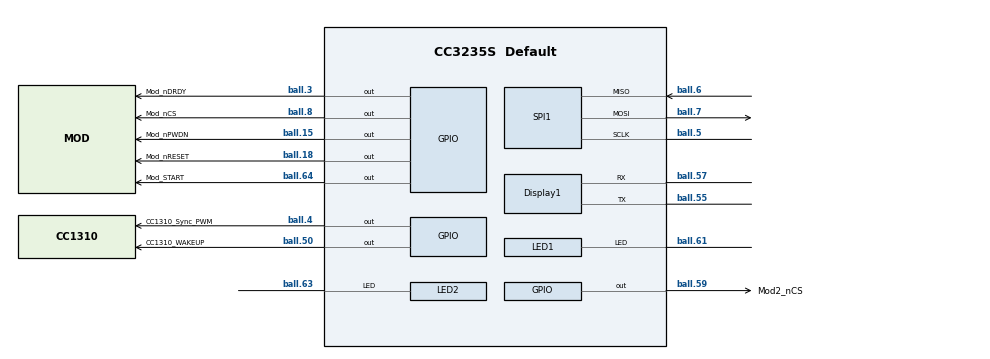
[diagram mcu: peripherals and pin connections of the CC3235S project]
/**
 * @cliArgs --device "CC3235S" --package "Default" --part "Default" --rtos "tirtos" --product "simplelink_cc32xx_sdk@5.30.00.08"
 * @versions {"tool":"1.10.0+2163"}
 */

/**
 * Import the modules used in this configuration.
 */
const DriverLib      = scripting.addModule("/ti/devices/DriverLib");
const Display        = scripting.addModule("/ti/display/Display");
const Display1       = Display.addInstance();
const Board          = scripting.addModule("/ti/drivers/Board");
const Crypto         = scripting.addModule("/ti/drivers/Crypto");
const Crypto1        = Crypto.addInstance();
const DMA            = scripting.addModule("/ti/drivers/DMA");
const GPIO           = scripting.addModule("/ti/drivers/GPIO");
const GPIO1          = GPIO.addInstance();
const GPIO2          = GPIO.addInstance();
const GPIO3          = GPIO.addInstance();
const GPIO4          = GPIO.addInstance();
const GPIO5          = GPIO.addInstance();
const GPIO6          = GPIO.addInstance();
const GPIO7          = GPIO.addInstance();
const GPIO8          = GPIO.addInstance();
const I2C            = scripting.addModule("/ti/drivers/I2C", {}, false);
const I2C1           = I2C.addInstance();
const Power          = scripting.addModule("/ti/drivers/Power");
const SPI            = scripting.addModule("/ti/drivers/SPI");
const SPI1           = SPI.addInstance();
const Timer          = scripting.addModule("/ti/drivers/Timer", {}, false);
const Timer1         = Timer.addInstance();
const Timer2         = Timer.addInstance();
const Watchdog       = scripting.addModule("/ti/drivers/Watchdog");
const Watchdog1      = Watchdog.addInstance();
const LED            = scripting.addModule("/ti/drivers/apps/LED", {}, false);
const LED1           = LED.addInstance();
const LED2           = LED.addInstance();
const SimpleLinkWifi = scripting.addModule("/ti/drivers/net/wifi/SimpleLinkWifi");
const net_utils      = scripting.addModule("/ti/drivers/net/wifi/net_utils", {}, false);
const net_utils1     = net_utils.addInstance();
const SNTP           = scripting.addModule("/ti/net/SNTP");
const SlNet          = scripting.addModule("/ti/net/SlNet");
const SlNet1         = SlNet.addInstance();
const JSON           = scripting.addModule("/ti/utils/JSON");

/**
 * Write custom configuration values to the imported modules.
 */
Display1.$name                          = "CONFIG_Display_0";
Display1.useUART2                       = false;
Display1.uart.$name                     = "CONFIG_UART_0";
Display1.uart.useDMA                    = true;
Display1.uart.uart.$assign              = "UART0";
Display1.uart.uart.txPin.$assign        = "ball.55";
Display1.uart.uart.rxPin.$assign        = "ball.57";
Display1.uart.uart.txDmaChannel.$assign = "UDMA_CH9";
Display1.uart.uart.rxDmaChannel.$assign = "UDMA_CH8";

Crypto1.$name = "CONFIG_Crypto_0";

GPIO1.$name           = "Mod_nPWDN";
GPIO1.mode            = "Output";
GPIO1.gpioPin.$assign = "ball.15";

GPIO2.$name           = "Mod_nRESET";
GPIO2.mode            = "Output";
GPIO2.outputStrength  = "High";
GPIO2.gpioPin.$assign = "ball.18";

GPIO3.mode            = "Output";
GPIO3.outputStrength  = "High";
GPIO3.$name           = "Mod_START";
GPIO3.gpioPin.$assign = "ball.64";

GPIO4.outputStrength   = "High";
GPIO4.interruptTrigger = "Falling Edge";
GPIO4.$name            = "Mod_nDRDY";
GPIO4.gpioPin.$assign  = "ball.3";

GPIO5.$name              = "Mod2_nCS";
GPIO5.mode               = "Output";
GPIO5.initialOutputState = "High";
GPIO5.gpioPin.$assign    = "ball.59";

GPIO6.$name           = "CC1310_Sync_PWM";
GPIO6.mode            = "Output";
GPIO6.gpioPin.$assign = "ball.4";

GPIO7.$name            = "CC1310_WAKEUP";
GPIO7.interruptTrigger = "Both Edges";
GPIO7.gpioPin.$assign  = "ball.50";

GPIO8.$name              = "Mod_nCS";
GPIO8.mode               = "Output";
GPIO8.initialOutputState = "High";
GPIO8.gpioPin.$assign    = "ball.8";

I2C1.$name = "COMMON_I2C";

Power.ioRetentionShutdown = ["GRP_1"];
Power.parkPins.$name      = "ti_drivers_power_PowerCC32XXPins0";

SPI1.$name                    = "CONFIG_SPI_0";
SPI1.defaultTxBufferValue     = "0";
SPI1.ssControl                = "SW";
SPI1.spi.$assign              = "SPI0";
SPI1.spi.sclkPin.$assign      = "ball.5";
SPI1.spi.misoPin.$assign      = "ball.6";
SPI1.spi.mosiPin.$assign      = "ball.7";
SPI1.spi.dmaRxChannel.$assign = "UDMA_CH6";
SPI1.spi.dmaTxChannel.$assign = "UDMA_CH7";

Timer1.timerType     = "32 Bits";
Timer1.$name         = "System_Timer";
Timer1.timer.$assign = "Timer0";

Timer2.$name             = "Sync_Timer";
Timer2.timerType         = "32 Bits";
Timer2.interruptPriority = "4";
Timer2.timer.$assign     = "Timer1";

Watchdog1.$name            = "CONFIG_WATCHDOG_0";
Watchdog1.watchdog.$assign = "WATCHDOG0";

LED1.$name                      = "LED_RED";
LED1.ledPin.$assign             = "ball.61";
LED1.gpioPin.initialOutputState = "High";

LED2.$name                      = "LED_GREEN";
LED2.ledPin.$assign             = "ball.63";
LED2.gpioPin.initialOutputState = "High";

net_utils1.$name = "CONFIG_NET_UTILS_0";

SlNet1.$name  = "CONFIG_SLNET";
SlNet1.ifName = "CC32xx";

/**
 * Pinmux solution for unlocked pins/peripherals. This ensures that minor changes to the automatic solver in a future
 * version of the tool will not impact the pinmux you originally saw.  These lines can be completely deleted in order to
 * re-solve from scratch.
 */
I2C1.i2c.$suggestSolution        = "I2C0";
I2C1.i2c.sdaPin.$suggestSolution = "ball.2";
I2C1.i2c.sclPin.$suggestSolution = "ball.1";
